# ESP32-C5-LP register map
Vendor: ESPRESSIF SYSTEMS (SHANGHAI) CO., LTD.; Series: ESP32 C-Series; File version: 1
CPU: RV32IMAC r0p0, little endian, no MPU, no FPU, 0 interrupt priority bits
Address unit: 32 bits
Registers are 32-bit, read-write, reset 0x0 unless marked. A register's access mark holds for its fields unless they carry their own. Offsets are from the block's base; [hi:lo] are bit positions.

## LPPERI — LPPERI Peripheral
Base 0x600B2800
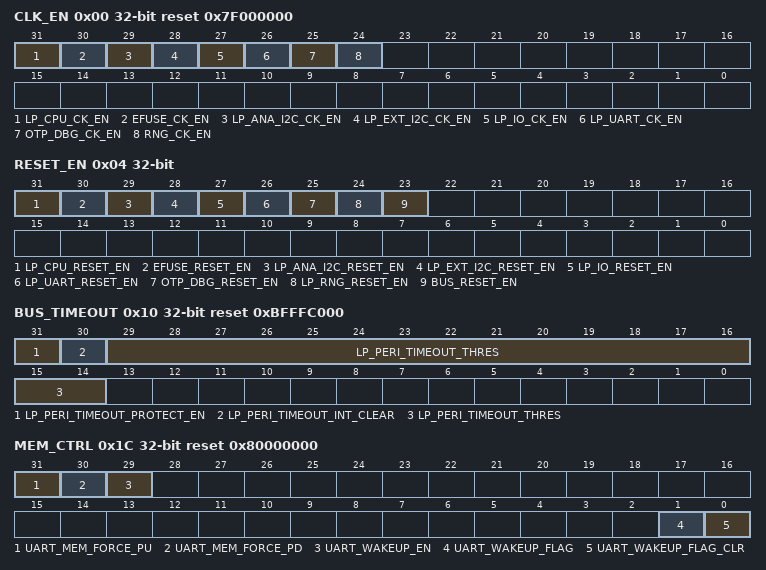
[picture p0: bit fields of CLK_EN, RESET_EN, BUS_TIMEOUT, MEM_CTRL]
0x00 CLK_EN reset 0x7F000000 — configure peri in lp system clk enable
  [31] LP_CPU_CK_EN — force on lp cpu clk enable 1: enable cpu clock 0: cpu clock is controlled by pmu
  [30] EFUSE_CK_EN — efuse core clk enable 1: enable clock 0: disable clock
  [29] LP_ANA_I2C_CK_EN — lp analog peri clk enable 1: enable clock 0: disable clock
  [28] LP_EXT_I2C_CK_EN — lp ext i2c clk enable 1: enable clock 0: disable clock
  [27] LP_IO_CK_EN — lp io clk enable 1: enable clock 0: disable clock
  [26] LP_UART_CK_EN — lp uart clk enable 1: enable clock 0: disable clock
  [25] OTP_DBG_CK_EN — lp optdebug clk enable 1: enable clock 0: disable clock
  [24] RNG_CK_EN — lp rng clk enable 1: enable clock 0: disable clock
0x04 RESET_EN access per field — configure peri in lp system reset enable
  [31] LP_CPU_RESET_EN wo — force on lp cpu reset enable 1: enable cpu reset 0: cpu reset is controlled by pmu
  [30] EFUSE_RESET_EN rw — efuse core reset enable 1: enable reset 0: disable reset
  [29] LP_ANA_I2C_RESET_EN rw — lp analog peri reset enable 1: enable reset 0: disable reset
  [28] LP_EXT_I2C_RESET_EN rw — lp ext i2c reset enable 1: enable reset 0: disable reset
  [27] LP_IO_RESET_EN rw — lp io reset enable 1: enable reset 0: disable reset
  [26] LP_UART_RESET_EN rw — lp uart reset enable 1: enable reset 0: disable reset
  [25] OTP_DBG_RESET_EN rw — lp optdebug reset enable 1: enable reset 0: disable reset
  [24] LP_RNG_RESET_EN rw — lp rng reset enable 1: enable reset 0: disable reset
  [23] BUS_RESET_EN wo — lp bus reset enable 1: enable reset 0: disable reset
0x08 RNG_DATA ro — RNG result register
  [31:0] RND_DATA — get rng data
0x0C CPU reset 0x80000000 — configure lp cpu dbg enable
  [31] LPCORE_DBGM_UNAVALIABLE — disable lp cpu dbg bus 1: disable 0: enable
0x10 BUS_TIMEOUT access per field reset 0xBFFFC000 — configure lp bus timeout
  [31] LP_PERI_TIMEOUT_PROTECT_EN rw — enable lp bus timeout or not,when bus timeout, the ready will been force high by fsm 1: enable 0: disable
  [30] LP_PERI_TIMEOUT_INT_CLEAR wo — clear lp bus timeout interrupt
  [29:14] LP_PERI_TIMEOUT_THRES rw — the timeout thres which bus access time, the timeout clk is lp_aon_fast
0x14 BUS_TIMEOUT_ADDR ro — the timeout address register
  [31:0] LP_PERI_TIMEOUT_ADDR — when bus timeout, this register will record the timeout address
0x18 BUS_TIMEOUT_UID ro — the timeout master id register
  [6:0] LP_PERI_TIMEOUT_UID — when bus timeout, this register will record the timeout master device
0x1C MEM_CTRL access per field reset 0x80000000 — configure uart memory power mode
  [31] UART_MEM_FORCE_PU rw — force on uart memory
  [30] UART_MEM_FORCE_PD rw — force off uart memory
  [29] UART_WAKEUP_EN rw — enable uart wakeup not not
  [1] UART_WAKEUP_FLAG rw — latch uart wakeup event
  [0] UART_WAKEUP_FLAG_CLR wo — clear uart wakeup latch 1: clear 0: no operation
0x20 INTERRUPT_SOURCE ro — record the lp cpu interrupt
  [5:0] LP_INTERRUPT_SOURCE — BIT5~BIT0: pmu_lp_int, modem_lp_int, lp_timer_lp_int, lp_uart_int, lp_i2c_int, lp_io_int
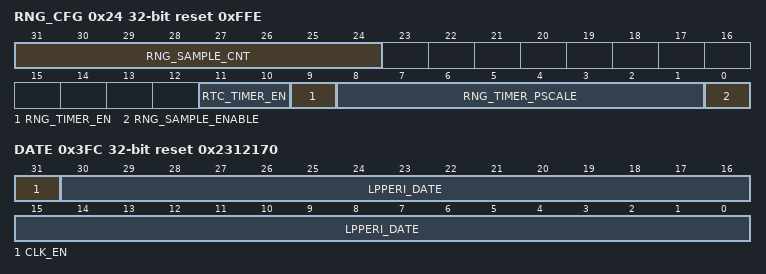
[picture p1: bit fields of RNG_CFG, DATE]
0x24 RNG_CFG access per field reset 0xFFE — configure rng register
  [31:24] RNG_SAMPLE_CNT ro — get rng RO sample cnt
  [11:10] RTC_TIMER_EN rw — enable rng xor rtc timer: bit(0) : enable rtc timer before crc Bit(1): enable rtc timer after crc
  [9] RNG_TIMER_EN rw — enable rng xor async rng timer
  [8:1] RNG_TIMER_PSCALE rw — configure rng timer clk div
  [0] RNG_SAMPLE_ENABLE rw — enable rng RO 1: enable RO 0: disable RO
0x28 RNG_DATA_SYNC ro — rng result sync register
  [31:0] RND_SYNC_DATA — get rng sync result
0x3FC DATE reset 0x2312170 — version register
  [31] CLK_EN — force on reg clk
  [30:0] LPPERI_DATE — version register
